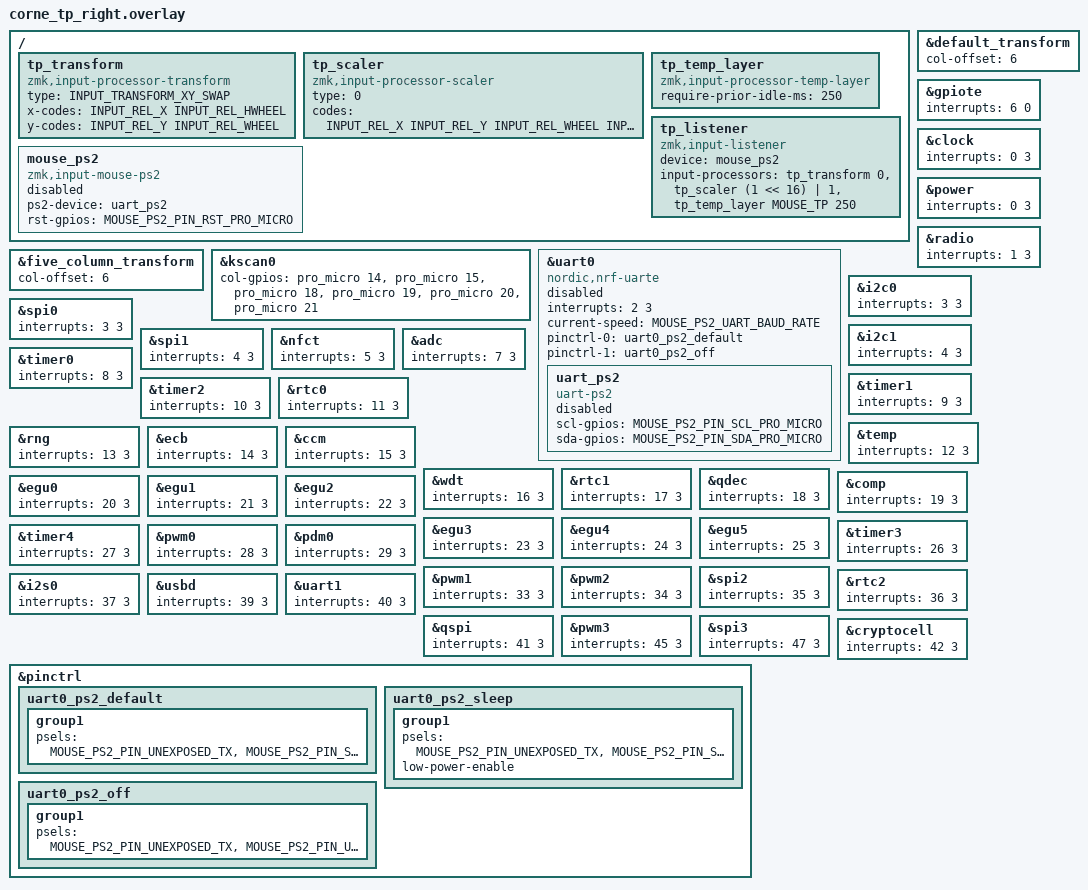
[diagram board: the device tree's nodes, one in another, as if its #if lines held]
/*
 * Copyright (c) 2020 Pete Johanson
 *
 * SPDX-License-Identifier: MIT
 */

#include "corne_tp.dtsi"

&default_transform {
    col-offset = <6>;
};

&five_column_transform {
    col-offset = <6>;
};

&kscan0 {
    col-gpios
        = <&pro_micro 14 GPIO_ACTIVE_HIGH>
        , <&pro_micro 15 GPIO_ACTIVE_HIGH>
        , <&pro_micro 18 GPIO_ACTIVE_HIGH>
        , <&pro_micro 19 GPIO_ACTIVE_HIGH>
        , <&pro_micro 20 GPIO_ACTIVE_HIGH>
        , <&pro_micro 21 GPIO_ACTIVE_HIGH>
        ;
};

/*
 * PS/2 Mouse / Trackpoint - User Configuration
 *
 * This half has the trackpoint connected and MUST be the central half.
 * It is configured as central in Kconfig.defconfig.
 */

#include <dt-bindings/zmk/input_transform.h>


// Pick the PS/2 driver: UART (recommended) or GPIO
//
// Leave the following define to use the PS/2 UART driver.
// Comment it out to use the PS/2 GPIO driver instead.
#define MOUSE_PS2_DRIVER_UART


// Configure the SCL and SDA pins using the `&pro_micro` notation.
//
// Ideal high-frequency pins on nice!nano: D1 (P0.06) and D0 (P0.08).
// But on Corne, these pins are used for underglow, so we use D16 and D10.
#define MOUSE_PS2_PIN_SCL_PRO_MICRO <&pro_micro 16 GPIO_ACTIVE_HIGH>
#define MOUSE_PS2_PIN_SDA_PRO_MICRO <&pro_micro 10 GPIO_ACTIVE_HIGH>

// Configure Power-On-Reset pin
// Uncomment if your trackpoint does not have a reset circuit.
// #define MOUSE_PS2_PIN_RST_PRO_MICRO <&pro_micro 9 GPIO_ACTIVE_HIGH>


// Configure UART pins using pinctrl notation
//
// nice!nano:
//   D10 is P0.09 -> 0, 9
//   D0  is P0.08 -> 0, 8
#define MOUSE_PS2_PIN_SDA_PINCTRL <NRF_PSEL(UART_RX, 0, 9)>

// Unexposed UART pins (do NOT change on nice!nano)
#define MOUSE_PS2_PIN_UNEXPOSED_TX <NRF_PSEL(UART_TX, 0, 27)>
#define MOUSE_PS2_PIN_UNEXPOSED_RX <NRF_PSEL(UART_RX, 0, 28)>

// UART baud rate for PS/2 protocol
#define MOUSE_PS2_UART_BAUD_RATE <14400>


/*
 * Input Processor Definitions
 *
 * These are used by the input-listener pipeline to transform
 * the raw trackpoint data before it's sent as HID reports.
 */

/ {
    /*
     * Transform input processor: swap and/or invert axes.
     */
    tp_transform: tp_transform {
        compatible = "zmk,input-processor-transform";
        status = "okay";
        type = <INPUT_TRANSFORM_XY_SWAP>;
        // type = <(INPUT_TRANSFORM_XY_SWAP | INPUT_TRANSFORM_X_INVERT)>;
        x-codes = <INPUT_REL_X INPUT_REL_HWHEEL>;
        y-codes = <INPUT_REL_Y INPUT_REL_WHEEL>;
    };

    /*
     * Scaler input processor: adjust sensitivity.
     * Values: (multiplier << 16) | divisor
     * Default: (1 << 16) | 1 = no scaling
     */
    tp_scaler: tp_scaler {
        compatible = "zmk,input-processor-scaler";
        status = "okay";
        type = <0>;              // RELATIVE
        codes = <INPUT_REL_X INPUT_REL_Y INPUT_REL_WHEEL INPUT_REL_HWHEEL>;
    };

    /*
     * Temporary layer input processor:
     * Activates layer MOUSE_TP (3) when the trackpoint moves
     * and deactivates it after inactivity.
     *
     * Parameters: (<layer>, <timeout-ms>)
     */
    tp_temp_layer: tp_temp_layer {
        compatible = "zmk,input-processor-temp-layer";
        status = "okay";
        require-prior-idle-ms = <250>;
    };

    /*
     * Input listener: the main entry point that ties everything together.
     * It subscribes to the PS/2 mouse device and runs the processors.
     */
    tp_listener: tp_listener {
        compatible = "zmk,input-listener";
        status = "okay";
        device = <&mouse_ps2>;

        input-processors =
            <&tp_transform 0>,
            <&tp_scaler    (1 << 16) | 1>,
            <&tp_temp_layer MOUSE_TP 250>;
    };
};


/*
 * PS/2 Device Tree Configuration
 *
 * Pin settings and hardware nodes for the PS/2 protocol driver.
 * Do not change anything beyond this point unless you know what you are doing.
 */

#define MOUSE_PS2_DT_PRESENT

/*
 * Adjust interrupt priorities for reliable PS/2 communication.
 * These override the default values to give PS/2 interrupts the highest priority.
 */

// gpiote should have the highest interrupt priority (0)
&gpiote {
    interrupts = < 6 0 >;
};

// All other priorities should be two levels lower than their defaults
&clock {
    interrupts = < 0 3 >;
};

&power {
    interrupts = < 0 3 >;
};

&radio {
    interrupts = < 1 3 >;
};

&uart0 {
    interrupts = < 2 3 >;
};

&i2c0 {
    interrupts = < 3 3 >;
};

&spi0 {
    interrupts = < 3 3 >;
};

&i2c1 {
    interrupts = < 4 3 >;
};

&spi1 {
    interrupts = < 4 3 >;
};

&nfct {
    interrupts = < 5 3 >;
};

&adc {
    interrupts = < 7 3 >;
};

&timer0 {
    interrupts = < 8 3 >;
};

&timer1 {
    interrupts = < 9 3 >;
};

&timer2 {
    interrupts = < 10 3 >;
};

&rtc0 {
    interrupts = < 11 3 >;
};

&temp {
    interrupts = < 12 3 >;
};

&rng {
    interrupts = < 13 3 >;
};

&ecb {
    interrupts = < 14 3 >;
};

&ccm {
    interrupts = < 15 3 >;
};

&wdt {
    interrupts = < 16 3 >;
};

&rtc1 {
    interrupts = < 17 3 >;
};

&qdec {
    interrupts = < 18 3 >;
};

&comp {
    interrupts = < 19 3 >;
};

&egu0 {
    interrupts = < 20 3 >;
};

&egu1 {
    interrupts = < 21 3 >;
};

&egu2 {
    interrupts = < 22 3 >;
};

&egu3 {
    interrupts = < 23 3 >;
};

&egu4 {
    interrupts = < 24 3 >;
};

&egu5 {
    interrupts = < 25 3 >;
};

&timer3 {
    interrupts = < 26 3 >;
};

&timer4 {
    interrupts = < 27 3 >;
};

&pwm0 {
    interrupts = < 28 3 >;
};

&pdm0 {
    interrupts = < 29 3 >;
};

&pwm1 {
    interrupts = < 33 3 >;
};

&pwm2 {
    interrupts = < 34 3 >;
};

&spi2 {
    interrupts = < 35 3 >;
};

&rtc2 {
    interrupts = < 36 3 >;
};

&i2s0 {
    interrupts = < 37 3 >;
};

&usbd {
    interrupts = < 39 3 >;
};

&uart1 {
    interrupts = < 40 3 >;
};

&qspi {
    interrupts = < 41 3 >;
};

&pwm3 {
    interrupts = < 45 3 >;
};

&spi3 {
    interrupts = < 47 3 >;
};

&cryptocell {
    interrupts = < 42 3 >;
};


/*
 * PS/2 Hardware Device Definitions
 *
 * Do not change anything beyond here.
 */

&pinctrl {
    // This pinctrl state is used for receiving
    uart0_ps2_default: uart0_ps2_default {
        group1 {
            psels = MOUSE_PS2_PIN_UNEXPOSED_TX,
                    MOUSE_PS2_PIN_SDA_PINCTRL;
        };
    };

    // Sleep state with the same pins, low-power enabled
    uart0_ps2_sleep: uart0_ps2_sleep {
        group1 {
            psels = MOUSE_PS2_PIN_UNEXPOSED_TX,
                    MOUSE_PS2_PIN_SDA_PINCTRL;
            low-power-enable;
        };
    };

    // Off state: moves to unexposed pins so the SDA pin is freed for GPIO bit-banging
    uart0_ps2_off: uart0_ps2_off {
        group1 {
            psels = MOUSE_PS2_PIN_UNEXPOSED_TX,
                    MOUSE_PS2_PIN_UNEXPOSED_RX;
        };
    };
};


#ifdef MOUSE_PS2_DRIVER_UART

    &uart0 {
        status = "disabled";
        compatible = "nordic,nrf-uarte";

        current-speed = MOUSE_PS2_UART_BAUD_RATE;
        pinctrl-0 = <&uart0_ps2_default>;
        pinctrl-1 = <&uart0_ps2_off>;

        pinctrl-names = "default", "sleep";

        uart_ps2: uart_ps2 {
            status="disabled";
            compatible = "uart-ps2";
            scl-gpios = MOUSE_PS2_PIN_SCL_PRO_MICRO;
            sda-gpios = MOUSE_PS2_PIN_SDA_PRO_MICRO;
        };
    };

#else

    / {
        gpio_ps2: gpio_ps2 {
            status = "disabled";
            compatible = "gpio-ps2";
            scl-gpios = MOUSE_PS2_PIN_SCL_PRO_MICRO;
            sda-gpios = MOUSE_PS2_PIN_SDA_PRO_MICRO;
        };
    };

#endif


/ {
    mouse_ps2: mouse_ps2 {
        status = "disabled";
        compatible = "zmk,input-mouse-ps2";

#ifdef MOUSE_PS2_DRIVER_UART
        ps2-device = <&uart_ps2>;
#else
        ps2-device = <&gpio_ps2>;
#endif

#ifdef MOUSE_PS2_PIN_RST_PRO_MICRO
        rst-gpios = MOUSE_PS2_PIN_RST_PRO_MICRO;
#endif
    };
};
